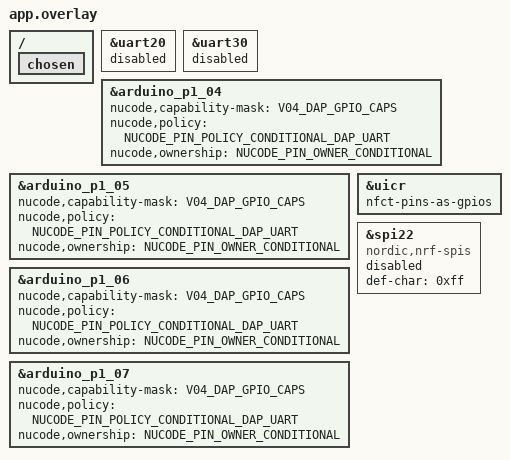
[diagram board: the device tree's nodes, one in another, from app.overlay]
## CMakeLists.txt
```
cmake_minimum_required(VERSION 3.20.0)
find_package(Zephyr REQUIRED HINTS $ENV{ZEPHYR_BASE})
project(v04pair LANGUAGES C CXX)
include(${CMAKE_CURRENT_SOURCE_DIR}/read_revision.cmake)
nucode_hil_revision("${CMAKE_CURRENT_SOURCE_DIR}/../../.." HIL_REVISION)
target_compile_definitions(app PRIVATE NUCODE_HIL_CORE_REVISION="${HIL_REVISION}")
target_sources(app PRIVATE src/main.cpp src/serial_hil.cpp src/fixture_hil.cpp
                           src/signal_hil.cpp)
```

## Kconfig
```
mainmenu "NU54DK v0.4 pair HIL"
source "Kconfig.zephyr"
config NUCODE_V04_HIL_ROLE
    int "Physical role: 1 DUT, 2 peer"
    range 1 2
    default 1
```

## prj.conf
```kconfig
CONFIG_CPP=y
CONFIG_STD_CPP17=y
CONFIG_CPP_EXCEPTIONS=n
CONFIG_CPP_RTTI=n
CONFIG_CONSOLE=n
CONFIG_SERIAL=n
CONFIG_PRINTK=n
CONFIG_LOG=n
CONFIG_ADC=n
CONFIG_PWM=n
CONFIG_I2S=n
CONFIG_SENSOR=n
CONFIG_NUCODE_ARDUINO_CORE=y
CONFIG_NUCODE_ARDUINO_RUNTIME=n
CONFIG_NUCODE_ARDUINO_API=y
CONFIG_NUCODE_ARDUINO_IO_OWNERSHIP=y
CONFIG_NUCODE_ARDUINO_IO_RESOURCE_SLOTS=128
CONFIG_NUCODE_ARDUINO_GPIO=y
CONFIG_NUCODE_ARDUINO_CONNECTOR_GPIO=y
CONFIG_NUCODE_ARDUINO_DAP_UART_GPIO_PINS=y
CONFIG_NUCODE_ARDUINO_INTERRUPTS=n
CONFIG_NUCODE_ARDUINO_TIME=n
CONFIG_NUCODE_ARDUINO_SERIAL=n
CONFIG_NUCODE_ARDUINO_SERIAL_FABRIC=y
CONFIG_NUCODE_ARDUINO_SERIAL_FABRIC_UARTE=y
CONFIG_NUCODE_ARDUINO_SERIAL_FABRIC_SPIM=y
CONFIG_NUCODE_ARDUINO_SERIAL_FABRIC_SPIS=y
CONFIG_NUCODE_ARDUINO_SERIAL_FABRIC_TWIM=y
CONFIG_NUCODE_ARDUINO_SERIAL_FABRIC_TWIS=y
CONFIG_NUCODE_ARDUINO_WIRE=n
CONFIG_NUCODE_ARDUINO_SPI=n
CONFIG_NUCODE_ARDUINO_ADC=n
CONFIG_NUCODE_ARDUINO_PWM=n
CONFIG_NUCODE_ARDUINO_ANALOG_FABRIC=y
CONFIG_NUCODE_ARDUINO_EVENT_FABRIC=y
CONFIG_NUCODE_ARDUINO_STREAM_FABRIC=y
CONFIG_MAIN_STACK_SIZE=8192
```

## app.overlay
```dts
#include <nucode/nu54dk-arduino-pins.dtsi>
/ {
    chosen {
        /delete-property/ zephyr,console;
        /delete-property/ zephyr,shell-uart;
        /delete-property/ zephyr,uart-mcumgr;
        /delete-property/ zephyr,bt-mon-uart;
        /delete-property/ zephyr,bt-c2h-uart;
    };
};
&uart20 { status = "disabled"; };
&uart30 { status = "disabled"; };

/**
 * @brief 이 HIL은 DAP UART 분리 확인 후에만 P1.04~07을 외부 fixture로 사용합니다.
 * @note 일반 board 정책은 유지하며 capability는 DAP UART GPIO Kconfig 조건을 따릅니다.
 */
#define V04_DAP_GPIO_CAPS (NUCODE_PIN_CAP_INPUT | NUCODE_PIN_CAP_OUTPUT | NUCODE_PIN_CAP_ANALOG)
&arduino_p1_04
{
    nucode,capability-mask = <V04_DAP_GPIO_CAPS>;
    nucode,policy = <NUCODE_PIN_POLICY_CONDITIONAL_DAP_UART>;
    nucode,ownership = <NUCODE_PIN_OWNER_CONDITIONAL>;
};
&arduino_p1_05
{
    nucode,capability-mask = <V04_DAP_GPIO_CAPS>;
    nucode,policy = <NUCODE_PIN_POLICY_CONDITIONAL_DAP_UART>;
    nucode,ownership = <NUCODE_PIN_OWNER_CONDITIONAL>;
};
&arduino_p1_06
{
    nucode,capability-mask = <V04_DAP_GPIO_CAPS>;
    nucode,policy = <NUCODE_PIN_POLICY_CONDITIONAL_DAP_UART>;
    nucode,ownership = <NUCODE_PIN_OWNER_CONDITIONAL>;
};
&arduino_p1_07
{
    nucode,capability-mask = <V04_DAP_GPIO_CAPS>;
    nucode,policy = <NUCODE_PIN_POLICY_CONDITIONAL_DAP_UART>;
    nucode,ownership = <NUCODE_PIN_OWNER_CONDITIONAL>;
};
#undef V04_DAP_GPIO_CAPS

/* P1.2/P1.3 are NFC pads unless explicitly released to the PMIC GPIO route. */
&uicr { nfct-pins-as-gpios; };

/* nrfx SPIS needs a compatible node, but no Zephyr driver may claim its IRQ. */
&spi22 {
    compatible = "nordic,nrf-spis";
    /delete-property/ rx-delay-supported;
    /delete-property/ rx-delay;
    def-char = <0xff>;
    status = "disabled";
};
```

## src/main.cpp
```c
// SPDX-License-Identifier: MIT
/** @brief 양쪽 DAP UART level shifter를 분리해도 SWD로 시험을 제어합니다. */
#include "protocol.h"
#include "serial_hil.h"
#include "fixture_hil.h"
#include "signal_hil.h"
#include "pwm_capture_hil.h"
#include "wiring_hil.h"
#include "common_gpio_hil.h"
#include "common_qdec_hil.h"
#include "common_i2s_hil.h"
#include <nucode/AnalogFabric.h>
#include <nucode/EventFabric.h>
#include <nucode/SerialFabric.h>
#include <variant.h>
#include <zephyr/kernel.h>

extern "C"
{
    alignas(4) volatile std::uint32_t v04_request[v04::words]{};
    alignas(4) volatile std::uint32_t v04_response[v04::words]{};
    alignas(4) volatile std::uint32_t v04_identity[16]{};
}

namespace
{
    using namespace nucode::arduino;
    constexpr std::uint32_t role = CONFIG_NUCODE_V04_HIL_ROLE;
    constexpr char revision[] = NUCODE_HIL_CORE_REVISION;
    static_assert(sizeof(revision) == 41);
    alignas(4) std::uint8_t twi_memory[8]{};
    alignas(4) std::int16_t adc_memory[32]{};
    alignas(4) std::uint16_t pwm20_memory[4]{250U, 0U, 0U, 0U};
    alignas(4) std::uint16_t pwm21_memory[4]{0U, 500U, 0U, 0U};

    /** @brief PMIC 시험은 외부 fixture가 해제된 상태에서 읽기 전용으로 실행합니다. */
    std::uint32_t pmic(const std::uint32_t *args, std::uint32_t *out, std::uint32_t &count)
    {
        const auto instance = args[0];
        const auto repeats = args[1];
        if ((instance != 20U && instance != 21U && instance != 22U) || repeats == 0 ||
            repeats > 100 || (args[2] != 100000 && args[2] != 400000))
        {
            return 400;
        }
        auto *handle = serialFabric().twim(instance);
        const SerialSignalPin pins[] = {{SerialSignal::sda, PIN_P1_02},
                                        {SerialSignal::scl, PIN_P1_03}};
        const SerialDmaWorkspace workspace{twi_memory, sizeof(twi_memory)};
        const SerialFabricConfiguration configuration{SerialRouteClass::p1_flexible,
                                                      SerialElectricalProfile::pmic_read_only,
                                                      pins,
                                                      2,
                                                      &workspace,
                                                      1};
        if (handle == nullptr ||
            handle->configure({static_cast<TwiFabricFrequency>(args[2])}) !=
                SerialFabricResult::success ||
            handle->stage(configuration) != SerialFabricResult::success ||
            handle->activate() != SerialFabricResult::success)
        {
            return 501;
        }
        out[0] = 0;
        for (std::uint32_t round = 0; round < repeats; ++round)
        {
            twi_memory[0] = 0x0c;
            twi_memory[1] = 0;
            const auto result = handle->transfer(0x6a, twi_memory, 1, twi_memory + 1, 1, 100000);
            out[3] = static_cast<std::uint32_t>(result);
            if (result != SerialFabricResult::success || twi_memory[1] != 0x41)
            {
                break;
            }
            ++out[0];
            TwiFabricEvent event{};
            while (handle->takeEvent(event))
            {
            }
        }
        out[1] = twi_memory[1];
        out[2] = static_cast<std::uint32_t>(handle->deactivate(100000));
        count = 4;
        return out[0] == repeats && out[2] == 0 ? 0 : 502;
    }

    std::uint32_t timerTest(const std::uint32_t *args, std::uint32_t *out, std::uint32_t &count)
    {
        const auto instance = args[0];
        if (instance != 0 && instance != 10 && (instance < 20 || instance > 24))
        {
            return 400;
        }
        auto *timer = eventFabric().timer(instance);
        if (!timer || args[1] >= timer->channelCount() || args[2] < 1000 || args[2] > 10000)
        {
            return 400;
        }
        if (timer->acquire(1000000) != EventFabricResult::success)
        {
            return 510;
        }
        const bool started = timer->clear() == EventFabricResult::success &&
                             timer->start() == EventFabricResult::success;
        if (started)
        {
            k_busy_wait(args[2]);
        }
        out[0] = timer->capture(args[1]);
        out[1] = static_cast<std::uint32_t>(timer->stop());
        out[2] = static_cast<std::uint32_t>(timer->release());
        count = 3;
        return started && out[1] == 0 && out[2] == 0 ? 0 : 511;
    }

    std::uint32_t adcTest(const std::uint32_t *args, std::uint32_t *out, std::uint32_t &count)
    {
        /** @brief 이 opcode는 외부 패드를 읽거나 구동하지 않는 입력 allowlist만 사용합니다. */
        if ((args[0] != 0x80 && args[0] != 0x82) || args[1] == 0 || args[1] > 32)
        {
            return 400;
        }
        auto &adc = analogFabric().saadc();
        const SaadcChannelConfiguration channel{static_cast<SaadcInput>(args[0]),
                                                SaadcInput::disabled, SaadcGain::one_quarter};
        if (adc.configure({&channel, 1, 12, 1, 0}) != AnalogFabricResult::success ||
            adc.start(adc_memory, args[1], nullptr, 0) != AnalogFabricResult::success)
        {
            return 520;
        }
        bool ready = false, complete = false, failed = false;
        std::uint32_t sampled = 0;
        const auto deadline = k_uptime_get() + 2000;
        while (!complete && !failed && k_uptime_get() < deadline)
        {
            SaadcEvent event{};
            while (adc.takeEvent(event))
            {
                if (event.type == SaadcEventType::ready)
                {
                    ready = true;
                }
                if (event.type == SaadcEventType::error)
                {
                    failed = true;
                }
                if (event.type == SaadcEventType::buffer_complete)
                {
                    complete = event.buffer == adc_memory && event.samples == args[1];
                    failed |= !complete;
                }
            }
            if (ready && sampled < args[1])
            {
                if (adc.sample() != AnalogFabricResult::success)
                {
                    failed = true;
                }
                else
                {
                    ++sampled;
                }
            }
            if (!complete)
            {
                k_sleep(K_MSEC(1));
            }
        }
        out[0] = sampled;
        out[1] = static_cast<std::uint32_t>(adc.stop(100000));
        out[2] = complete ? 1U : 0U;
        if (out[1] != 0)
        {
            count = 3;
            return 522;
        }
        std::int16_t lowest = adc_memory[0], highest = adc_memory[0];
        for (std::size_t index = 0; index < args[1]; ++index)
        {
            if (adc_memory[index] < lowest)
            {
                lowest = adc_memory[index];
            }
            if (adc_memory[index] > highest)
            {
                highest = adc_memory[index];
            }
        }
        out[3] = static_cast<std::uint32_t>(static_cast<std::int32_t>(lowest));
        out[4] = static_cast<std::uint32_t>(static_cast<std::int32_t>(highest));
        count = 5;
        return complete && !failed && out[1] == 0 ? 0 : 521;
    }

    /** @brief 배선 없이 PWM20·PWM21·SAADC EasyDMA가 동시에 활성화되는지 검사합니다. */
    std::uint32_t concurrentAnalogTest(std::uint32_t *out, std::uint32_t &count)
    {
        auto *const pwm20 = analogFabric().pwm(20U);
        auto *const pwm21 = analogFabric().pwm(21U);
        auto &adc = analogFabric().saadc();
        PwmSequenceConfiguration first{};
        PwmSequenceConfiguration second{};
        first.output_pins[0] = PIN_P1_10;
        second.output_pins[1] = PIN_P1_14;
        first.top_value = second.top_value = 1000U;
        first.load = second.load = PwmSequenceLoad::individual;
        const SaadcChannelConfiguration channel{SaadcInput::vdd, SaadcInput::disabled,
                                                SaadcGain::one_quarter};
        if (pwm20 == nullptr || pwm21 == nullptr ||
            pwm20->configure(first) != AnalogFabricResult::success ||
            pwm21->configure(second) != AnalogFabricResult::success)
        {
            return 530U;
        }
        if (pwm20->play({pwm20_memory, 4U, 0U, 0U}, nullptr, 100U, false) !=
            AnalogFabricResult::success)
        {
            return 530U;
        }
        if (pwm21->play({pwm21_memory, 4U, 0U, 0U}, nullptr, 100U, false) !=
            AnalogFabricResult::success)
        {
            (void)pwm20->stop(100000U);
            return 530U;
        }
        if (adc.configure({&channel, 1U, 12U, 1U, 0U}) != AnalogFabricResult::success ||
            adc.start(adc_memory, 32U, nullptr, 0U) != AnalogFabricResult::success)
        {
            (void)pwm21->stop(100000U);
            (void)pwm20->stop(100000U);
            return 530U;
        }
        const bool simultaneous = pwm20->state() == AnalogFabricState::active &&
                                  pwm21->state() == AnalogFabricState::active &&
                                  adc.state() == AnalogFabricState::active;
        bool adc_ready = false;
        bool adc_complete = false;
        bool pwm20_complete = false;
        bool pwm21_complete = false;
        bool failed = false;
        std::uint32_t sampled = 0U;
        const auto deadline = k_uptime_get() + 2000;
        while ((!adc_complete || !pwm20_complete || !pwm21_complete) && !failed &&
               k_uptime_get() < deadline)
        {
            SaadcEvent adc_event{};
            while (adc.takeEvent(adc_event))
            {
                adc_ready |= adc_event.type == SaadcEventType::ready;
                adc_complete |= adc_event.type == SaadcEventType::buffer_complete &&
                                adc_event.buffer == adc_memory && adc_event.samples == 32U;
                failed |= adc_event.type == SaadcEventType::error;
            }
            PwmSequenceEvent pwm_event{};
            while (pwm20->takeEvent(pwm_event))
            {
                pwm20_complete |= pwm_event.type == PwmSequenceEventType::playback_complete;
                failed |= pwm_event.type == PwmSequenceEventType::error;
            }
            while (pwm21->takeEvent(pwm_event))
            {
                pwm21_complete |= pwm_event.type == PwmSequenceEventType::playback_complete;
                failed |= pwm_event.type == PwmSequenceEventType::error;
            }
            if (adc_ready && sampled < 32U)
            {
                if (adc.sample() != AnalogFabricResult::success)
                {
                    failed = true;
                }
                else
                {
                    ++sampled;
                }
            }
            k_sleep(K_MSEC(1));
        }
        const auto adc_stop = adc.stop(100000U);
        const auto pwm21_stop = pwm21->stop(100000U);
        const auto pwm20_stop = pwm20->stop(100000U);
        out[0] = simultaneous;
        out[1] = sampled;
        out[2] = adc_complete;
        out[3] = pwm20_complete;
        out[4] = pwm21_complete;
        out[5] = static_cast<std::uint32_t>(adc_stop);
        out[6] = static_cast<std::uint32_t>(pwm20_stop);
        out[7] = static_cast<std::uint32_t>(pwm21_stop);
        count = 8U;
        return simultaneous && sampled == 32U && adc_complete && pwm20_complete && pwm21_complete &&
                       !failed && adc_stop == AnalogFabricResult::success &&
                       pwm20_stop == AnalogFabricResult::success &&
                       pwm21_stop == AnalogFabricResult::success
                   ? 0U
                   : 531U;
    }

    std::uint32_t dispatch(std::uint32_t opcode, const std::uint32_t *args, std::uint32_t nargs,
                           std::uint32_t *out, std::uint32_t &count)
    {
        if (opcode == 1 && nargs == 4)
        {
            count = 4;
            for (unsigned index = 0; index < count; ++index)
            {
                out[index] = args[index] ^ (0xa5000000U | role);
            }
            return 0;
        }
        if (opcode >= 88U && opcode <= 95U)
        {
            return commonI2sCommand(opcode, args, nargs, out, count);
        }
        if (commonI2sClaimed())
        {
            return 403U;
        }
        if (opcode >= 80U && opcode <= 87U)
        {
            return commonQdecCommand(opcode, args, nargs, out, count);
        }
        if (commonQdecClaimed())
        {
            return 403U;
        }
        if (opcode >= 64U && opcode <= 73U)
        {
            return commonGpioCommand(opcode, args, nargs, out, count);
        }
        if (commonGpioClaimed())
        {
            return 403U;
        }
        if (opcode >= 48U && opcode <= 53U)
        {
            return wiringCommand(opcode, args, nargs, out, count);
        }
        if (wiringClaimed())
        {
            return 403U;
        }
        if ((opcode >= 40U && opcode <= 47U) || (opcode >= 54U && opcode <= 59U))
        {
            return pwmCaptureCommand(opcode, args, nargs, out, count);
        }
        if (pwmCaptureClaimed())
        {
            return 403U;
        }
        if (opcode >= 16 && opcode <= 28)
        {
            return fixtureCommand(opcode, args, nargs, out, count);
        }
        if (opcode >= 32 && opcode <= 39)
        {
            return signalCommand(opcode, args, nargs, out, count);
        }
        if (fixtureClaimed() || signalClaimed())
        {
            return 403;
        }
        if (opcode == 2 && nargs == 3)
        {
            return pmic(args, out, count);
        }
        if (opcode == 3 && nargs == 3)
        {
            return timerTest(args, out, count);
        }
        if (opcode == 4 && nargs == 2)
        {
            return adcTest(args, out, count);
        }
        if (opcode == 5 && nargs == 0)
        {
            return concurrentAnalogTest(out, count);
        }
        if (opcode >= 9 && opcode <= 13)
        {
            return serialOnboard(opcode, args, nargs, out, count);
        }
        return 400;
    }
} // namespace

int main()
{
    initializeWiringIdle();
    initializeOnboardSerialIdle();
    v04_identity[1] = v04::version;
    v04_identity[2] = role;
    for (unsigned index = 0; index < 10; ++index)
    {
        std::uint32_t word = 0;
        for (unsigned byte = 0; byte < 4; ++byte)
        {
            word |= static_cast<std::uint32_t>(revision[index * 4 + byte]) << (byte * 8);
        }
        v04_identity[4 + index] = word;
    }
    __DMB();
    v04_identity[0] = v04::magic;
    std::uint32_t last_sequence = 0;
    std::uint32_t session_nonce[4]{};
    while (true)
    {
        serviceSerial();
        serviceFixture();
        serviceSignal();
        servicePwmCapture();
        serviceWiring();
        serviceCommonGpio();
        serviceCommonQdec();
        serviceCommonI2s();
        if (v04_request[0] != v04::magic)
        {
            if (signalNeedsPolling() || commonGpioNeedsPolling() || commonQdecNeedsPolling() ||
                commonI2sNeedsPolling() || pwmCaptureNeedsPolling())
            {
                k_busy_wait(10U);
            }
            else
            {
                k_sleep(K_MSEC(1));
            }
            continue;
        }
        __DMB();
        std::uint32_t request[v04::words]{}, response[v04::words]{};
        for (unsigned index = 0; index < v04::words; ++index)
        {
            request[index] = v04_request[index];
        }
        v04_request[0] = 0;
        for (unsigned index = 0; index < 9; ++index)
        {
            response[index] = request[index];
        }
        bool same_nonce = true;
        for (unsigned index = 0; index < 4; ++index)
        {
            same_nonce &= request[5 + index] == session_nonce[index];
        }
        if (!v04::valid(request, role) || request[2] != last_sequence + 1 ||
            (last_sequence != 0 && !same_nonce))
        {
            response[9] = 409;
        }
        else
        {
            for (unsigned index = 0; index < 4; ++index)
            {
                session_nonce[index] = request[5 + index];
            }
            last_sequence = request[2];
            response[9] =
                dispatch(request[4], request + 11, request[10], response + 11, response[10]);
        }
        response[31] = v04::checksum(response);
        v04_response[0] = 0;
        for (unsigned index = 1; index < v04::words; ++index)
        {
            v04_response[index] = response[index];
        }
        __DMB();
        v04_response[0] = v04::magic;
    }
}
```

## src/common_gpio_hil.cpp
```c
/**
 * @file common_gpio_hil.cpp
 * @brief 공통 17신호에서 실제 Arduino GPIO와 GPIOTE API를 검사합니다.
 * @note 에지 발생은 CPU가 고정 GPIOTE task를 호출하는 진단 신호원입니다.
 * 정밀 주기나 IRQ latency를 보증하지 않으며 실제 count와 최대 poll 간격을 보고합니다.
 * SPDX-License-Identifier: MIT
 */
#include "common_gpio_hil.h"
#include "common_wiring.h"
#include "fixture_gate.h"
#include "fixture_hil.h"
#include "pwm_capture_hil.h"
#include "signal_hil.h"
#include "wiring_hil.h"
#include "serial_hil.h"
#include <Arduino.h>
#include <variant.h>
#include <internal/PinHandover.h>
#include <internal/pin_description.h>
#include <nucode/EventFabric.h>
#include <hal/nrf_gpio.h>
#include <hal/nrf_gpiote.h>
#include <zephyr/kernel.h>

namespace
{
    using namespace nucode::arduino;
    using namespace nucode::arduino::internal;
    constexpr std::uint32_t role = CONFIG_NUCODE_V04_HIL_ROLE;
    v04::FixtureGate gate;
    std::uint32_t net = v04::wiring_none;
    bool gpio_owned = false, gpiote_owned = false;
    bool output = false, generating = false;
    GpioteFabric *gpiote = nullptr;
    std::uint32_t channel = 0U, edge_count = 0U, emitted = 0U, error = 0U;
    std::uint32_t limit = 0U, interval_cycles = 0U, last_edge = 0U, last_poll = 0U;
    std::uint32_t max_poll_cycles = 0U, leakage = 0U, lease_expirations = 0U;

    /** @brief Arduino ID와 물리 net을 분리하고 I2S의 두 교차 선을 반영합니다. */
    pin_size_t logical(std::uint32_t selected)
    {
        constexpr pin_size_t pins[]{PIN_P1_14, PIN_P1_10, PIN_P1_04, PIN_P1_05, PIN_P1_06,
                                    PIN_P1_07, PIN_P0_00, PIN_P0_01, PIN_P0_02, PIN_P0_03,
                                    PIN_P2_00, PIN_P2_01, PIN_P2_02, PIN_P2_03, PIN_P2_04,
                                    PIN_P2_05, PIN_P2_06};
        if (selected >= v04::wiring_count)
        {
            return static_cast<pin_size_t>(UINT16_MAX);
        }
        return pins[role == 2U && (selected == 4U || selected == 5U) ? 9U - selected : selected];
    }

    /** @brief 현재 소유한 GPIOTE 레지스터만 진단 대상으로 선택합니다. */
    NRF_GPIOTE_Type *reg()
    {
        return gpiote != nullptr && gpiote->instance() == 30U ? NRF_GPIOTE30 : NRF_GPIOTE20;
    }

    /** @brief GPIO 입력 전환 뒤 내부 handover로 GPIO lease도 반환합니다. */
    bool releaseGpio()
    {
        if (!gpio_owned)
        {
            return true;
        }
        pinMode(logical(net), INPUT);
        if (lastGpioError() != GpioError::none)
        {
            return false;
        }
        GpioPinHandover handover{};
        if (beginGpioPinHandover(logical(net), {IoOwnerKind::application, 242U}, handover) !=
            PinHandoverResult::success)
        {
            return false;
        }
        if (commitGpioPinHandover(handover) != PinHandoverResult::success)
        {
            return false;
        }
        nrf_gpio_cfg_input(v04::wiringPin(role, net), NRF_GPIO_PIN_NOPULL);
        if (releasePeripheralPinHandover(handover) != PinHandoverResult::success)
        {
            return false;
        }
        gpio_owned = false;
        return true;
    }

    /** @brief 생성기를 먼저 중지한 뒤 검증 가능한 입력·free 상태로 돌립니다. */
    bool stop()
    {
        generating = false;
        if (gpiote_owned)
        {
            if (gpiote->release(static_cast<std::uint8_t>(channel)) != EventFabricResult::success)
            {
                return false;
            }
            gpiote_owned = false;
        }
        if (!releaseGpio())
        {
            return false;
        }
        if (net != v04::wiring_none &&
            nrf_gpio_pin_dir_get(v04::wiringPin(role, net)) != NRF_GPIO_PIN_DIR_INPUT)
        {
            return false;
        }
        net = v04::wiring_none;
        output = false;
        gpiote = nullptr;
        return true;
    }

    /** @brief 다른 신호를 구동하지 않았는지 전체 net의 방향을 원본으로 반환합니다. */
    std::uint32_t directionMask()
    {
        std::uint32_t mask = 0U;
        for (unsigned index = 0U; index < v04::wiring_count; ++index)
        {
            mask |=
                (nrf_gpio_pin_dir_get(v04::wiringPin(role, index)) == NRF_GPIO_PIN_DIR_OUTPUT ? 1U
                                                                                              : 0U)
                << index;
        }
        return mask;
    }

    /** @brief API 판정 전에 물리 level·설정·상태·누출을 그대로 제공합니다. */
    void snapshot(std::uint32_t *out, std::uint32_t &count)
    {
        out[0] = net;
        out[1] = net == v04::wiring_none ? 0U : nrf_gpio_pin_read(v04::wiringPin(role, net));
        out[2] = gpio_owned ? static_cast<std::uint32_t>(digitalRead(logical(net))) : UINT32_MAX;
        out[3] = directionMask();
        out[4] = 0U;
        if (net != v04::wiring_none)
        {
            auto physical = v04::wiringPin(role, net);
            auto *const port = nrf_gpio_pin_port_decode(&physical);
            out[4] = port->PIN_CNF[physical];
        }
        out[5] = edge_count;
        out[6] = emitted;
        out[7] = generating;
        out[8] = error;
        out[9] = leakage;
        out[10] = k_cyc_to_us_floor32(max_poll_cycles);
        out[11] = lease_expirations;
        out[12] = gpiote == nullptr ? 0U : gpiote->channelCount();
        out[13] = gpio_owned;
        out[14] = gpiote_owned;
        out[15] = gate.live(k_uptime_get());
        count = 16U;
    }
} // namespace

bool commonGpioClaimed()
{
    return gate.claimed();
}

bool commonGpioNeedsPolling()
{
    return gpiote_owned;
}

void serviceCommonGpio()
{
    if (gate.fixture() && !gate.live(k_uptime_get()))
    {
        ++lease_expirations;
        error = 1U;
        gate.close(stop());
    }
    if (!gpiote_owned)
    {
        return;
    }
    const auto now = k_cycle_get_32();
    const auto gap = now - last_poll;
    if (last_poll != 0U && gap > max_poll_cycles)
    {
        max_poll_cycles = gap;
    }
    last_poll = now;
    if (generating && now - last_edge >= interval_cycles)
    {
        last_edge = now;
        *reinterpret_cast<volatile std::uint32_t *>(gpiote->outTask(channel).address) = 1U;
        ++emitted;
        if (emitted == limit)
        {
            generating = false;
        }
    }
    for (unsigned index = 0U; index < gpiote->channelCount(); ++index)
    {
        const auto event = nrf_gpiote_in_event_get(index);
        if (nrf_gpiote_event_check(reg(), event))
        {
            nrf_gpiote_event_clear(reg(), event);
            if (index == channel && !output)
            {
                ++edge_count;
            }
            else
            {
                leakage |= 1U << index;
            }
        }
    }
}

std::uint32_t commonGpioCommand(std::uint32_t opcode, const std::uint32_t *args,
                                std::uint32_t nargs, std::uint32_t *out, std::uint32_t &count)
{
    serviceCommonGpio();
    if (opcode == 64U && nargs == 4U)
    {
        if (fixtureClaimed() || signalClaimed() || pwmCaptureClaimed() || wiringClaimed() ||
            onboardSerialActive() || args[0] != 502U ||
            !gate.arm(args[0], args[1], args[2], args[3], role, k_uptime_get()))
        {
            return 403U;
        }
        error = edge_count = emitted = leakage = max_poll_cycles = last_poll = 0U;
        out[0] = 502U;
        out[1] = 10000U;
        count = 2U;
        return 0U;
    }
    if (opcode == 65U && nargs == 0U)
    {
        const bool result = stop();
        gate.close(result);
        snapshot(out, count);
        return result ? 0U : 760U;
    }
    if (opcode == 68U && nargs == 0U)
    {
        snapshot(out, count);
        return 0U;
    }
    if (!gate.live(k_uptime_get()))
    {
        return 403U;
    }
    if (opcode == 69U && nargs == 0U)
    {
        out[0] = gate.renew(k_uptime_get()) ? 0U : 1U;
        count = 1U;
        return 0U;
    }
    if (opcode == 66U && nargs == 2U && args[0] < v04::wiring_count && args[1] < 5U &&
        !gpiote_owned && (net == v04::wiring_none || net == args[0]) &&
        (args[1] < 3U || gate.controller() == role))
    {
        constexpr PinMode modes[]{INPUT, INPUT_PULLUP, INPUT_PULLDOWN, OUTPUT, OUTPUT_OPENDRAIN};
        net = args[0];
        pinMode(logical(net), modes[args[1]]);
        out[0] = static_cast<std::uint32_t>(lastGpioError());
        gpio_owned |= out[0] == 0U;
        output = args[1] >= 3U && out[0] == 0U;
        count = 1U;
        return 0U;
    }
    if (opcode == 67U && nargs == 1U && args[0] <= 1U && gpio_owned && output &&
        gate.controller() == role)
    {
        digitalWrite(logical(net), args[0] ? HIGH : LOW);
        out[0] = static_cast<std::uint32_t>(lastGpioError());
        count = 1U;
        return 0U;
    }
    if (opcode == 70U && nargs == 4U && args[0] < 10U && args[1] < 8U && args[2] < 3U &&
        args[3] <= 1U && !gpio_owned && !gpiote_owned && net == v04::wiring_none &&
        (args[3] == 0U || gate.controller() == role))
    {
        net = args[0];
        channel = args[1];
        output = args[3] != 0U;
        gpiote = eventFabric().gpiote(net < 6U ? 20U : 30U);
        const auto polarity = static_cast<GpiotePolarity>(args[2]);
        const auto result = output ? gpiote->acquireOutput(channel, logical(net), polarity, false)
                                   : gpiote->acquireInput(channel, logical(net), polarity);
        gpiote_owned = result == EventFabricResult::success;
        out[0] = static_cast<std::uint32_t>(result);
        out[1] = gpiote->channelCount();
        count = 2U;
        if (gpiote_owned)
        {
            for (unsigned index = 0U; index < gpiote->channelCount(); ++index)
            {
                nrf_gpiote_event_clear(reg(), nrf_gpiote_in_event_get(index));
            }
        }
        return 0U;
    }
    if (opcode == 71U && nargs == 1U && args[0] < 3U && gpiote_owned && output && !generating)
    {
        const auto endpoint = args[0] == 0U   ? gpiote->outTask(channel)
                              : args[0] == 1U ? gpiote->setTask(channel)
                                              : gpiote->clearTask(channel);
        *reinterpret_cast<volatile std::uint32_t *>(endpoint.address) = 1U;
        out[0] = 0U;
        count = 1U;
        return 0U;
    }
    if (opcode == 72U && nargs == 2U && (args[0] == 100U || args[0] == 1000U) && args[1] == 1000U &&
        gpiote_owned && output && !generating && emitted == 0U)
    {
        interval_cycles = k_us_to_cyc_ceil32(1000000U / args[0]);
        limit = args[1];
        last_edge = k_cycle_get_32();
        generating = true;
        out[0] = 0U;
        count = 1U;
        return 0U;
    }
    if (opcode == 73U && nargs == 1U && args[0] < 3U && !gpio_owned && !gpiote_owned)
    {
        out[1] = directionMask();
        if (args[0] == 0U)
        {
            pinMode(static_cast<pin_size_t>(UINT16_MAX), OUTPUT);
            out[0] = static_cast<std::uint32_t>(lastGpioError());
        }
        else
        {
            auto *const handle = eventFabric().gpiote(args[0] == 1U ? 20U : 30U);
            const auto selected = args[0] == 1U ? handle->channelCount() : 0U;
            const auto result = handle->acquireInput(selected, PIN_P1_14, GpiotePolarity::toggle);
            out[0] = static_cast<std::uint32_t>(result);
            if (result == EventFabricResult::success)
            {
                /** @brief 예상 밖 성공도 입력만 획득했으며 즉시 반환하고 실패로 보고합니다. */
                (void)handle->release(selected);
            }
        }
        out[2] = directionMask();
        count = 3U;
        return 0U;
    }
    return 400U;
}
```

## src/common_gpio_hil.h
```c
/**
 * @file common_gpio_hil.h
 * @brief 공통 결선의 Arduino GPIO와 GPIOTE 기능 명령을 선언합니다.
 * SPDX-License-Identifier: MIT
 */
#pragma once
#include <cstdint>

/** @brief 다른 fixture와 배타적으로 사용하는 실행 상태입니다. */
bool commonGpioClaimed();
/** @brief 유한 에지 생성·관측과 10초 lease 만료를 처리합니다. */
void serviceCommonGpio();
/** @brief 에지를 놓치지 않도록 짧은 main poll이 필요한지 반환합니다. */
bool commonGpioNeedsPolling();
/** @brief 고정 net만 허용하는 GPIO/GPIOTE 명령입니다. */
std::uint32_t commonGpioCommand(std::uint32_t opcode, const std::uint32_t *args,
                                std::uint32_t nargs, std::uint32_t *out, std::uint32_t &count);
```

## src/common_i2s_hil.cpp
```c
/**
 * @file common_i2s_hil.cpp
 * @brief 3개 DMA slot을 순환하며 초기 4개와 측정 100개 buffer를 보존합니다.
 * @note 이후 Host STOP까지 공급한 tail은 측정 100개에 더하지 않습니다.
 * SPDX-License-Identifier: MIT
 */
#include "common_i2s_hil.h"
#include "common_qdec_hil.h"
#include "common_gpio_hil.h"
#include "common_wiring.h"
#include "fixture_gate.h"
#include "fixture_hil.h"
#include "pwm_capture_hil.h"
#include "signal_hil.h"
#include "wiring_hil.h"
#include "serial_hil.h"
#include "i2s_stream_oracle.h"
#include <nucode/StreamFabric.h>
#include <variant.h>
#include <hal/nrf_gpio.h>
#include <zephyr/kernel.h>

namespace
{
    using namespace nucode::arduino;
    constexpr std::uint32_t role = CONFIG_NUCODE_V04_HIL_ROLE;
    constexpr std::uint32_t slots = 3U, measured_end = 104U, guard = 0xA55A9669U;
    struct alignas(4) Buffer
    {
        std::uint32_t memory[1032];
        /** @brief 요청 길이 직후에 16-byte guard를 두며 capacity 끝으로 미루지 않습니다. */
        std::uint32_t *data()
        {
            return memory + 4U;
        }
    } rx[slots]{}, tx[slots]{};
    v04::FixtureGate gate;
    I2sFabric *i2s = nullptr;
    v04::I2sStreamOracle oracle;
    bool prepared = false, started = false, receive = false, transmit = false;
    bool active_slots[slots]{};
    std::uint32_t completed = 0U, queued = 0U, error = 0U, rate = 0U, width = 0U;
    std::uint32_t channels = 0U, words = 0U, seed = 0U, origin = 0U, max_queue_us = 0U;
    std::uint32_t lease_expirations = 0U;
    std::uint32_t statistics[measured_end][5]{};

    /** @brief slot의 앞뒤 guard를 요청 길이에 맞추어 설정합니다. */
    void initialize(Buffer &buffer)
    {
        for (unsigned index = 0U; index < 4U; ++index)
        {
            buffer.memory[index] = buffer.memory[words + 4U + index] = guard;
        }
    }

    /** @brief 측정/대기/활성 slot 모두의 앞뒤 guard를 읽습니다. */
    bool guards()
    {
        for (unsigned slot = 0U; slot < slots; ++slot)
        {
            for (unsigned index = 0U; index < 4U; ++index)
            {
                if (rx[slot].memory[index] != guard ||
                    rx[slot].memory[words + 4U + index] != guard ||
                    tx[slot].memory[index] != guard || tx[slot].memory[words + 4U + index] != guard)
                {
                    return false;
                }
            }
        }
        return true;
    }

    /** @brief 순환 slot에 다음 고유 전역 word 위치를 채웁니다. */
    void fill(std::uint32_t slot, std::uint32_t index)
    {
        for (unsigned word = 0U; word < words; ++word)
        {
            tx[slot].data()[word] = v04::i2sStreamPattern(seed, index * words + word);
            rx[slot].data()[word] = 0xCCCCCCCCU;
        }
    }

    /** @brief 한쪽 DMA를 비활성화할 때는 실제 nullptr로 전달합니다. */
    I2sBuffers buffers(std::uint32_t slot)
    {
        return {receive ? rx[slot].data() : nullptr, transmit ? tx[slot].data() : nullptr, words};
    }

    /** @brief STOP이 증명된 뒤에만 stream과 pin을 반환합니다. */
    bool stop()
    {
        if (i2s != nullptr && i2s->state() == StreamFabricState::faulted)
        {
            return false;
        }
        if (i2s != nullptr && (i2s->state() == StreamFabricState::active ||
                               i2s->state() == StreamFabricState::stopping))
        {
            if (i2s->stop(100000U) != StreamFabricResult::success)
            {
                return false;
            }
            for (unsigned pin = 4U; pin <= 7U; ++pin)
            {
                nrf_gpio_cfg_input(NRF_GPIO_PIN_MAP(1, pin), NRF_GPIO_PIN_NOPULL);
            }
        }
        started = prepared = false;
        i2s = nullptr;
        return true;
    }

    /** @brief 완료와 재사용 전에 반환 pointer·크기·guard를 검증합니다. */
    void released(const I2sBuffers &result)
    {
        const auto slot = completed % slots;
        const auto expected = buffers(slot);
        if (!active_slots[slot] || result.receive != expected.receive ||
            result.transmit != expected.transmit || result.words != words || !guards())
        {
            error = 2U;
            return;
        }
        active_slots[slot] = false;
        if (completed < measured_end)
        {
            const auto mask = width == 24U ? 0xFFFFFFU : UINT32_MAX;
            auto crc = UINT32_MAX;
            for (unsigned index = 0U; index < words; ++index)
            {
                if (receive)
                {
                    const auto raw = result.receive[index];
                    oracle.consume(raw);
                    crc = v04::i2sCrcWord(crc, raw & mask);
                }
            }
            statistics[completed][0] = completed;
            statistics[completed][1] = k_cyc_to_us_floor32(k_cycle_get_32() - origin);
            statistics[completed][2] = receive ? crc ^ UINT32_MAX : 0U;
            statistics[completed][3] = receive ? result.receive[0] & mask : 0U;
            statistics[completed][4] = receive ? result.receive[words - 1U] & mask : 0U;
            if (oracle.mismatches != 0U)
            {
                error = 3U;
            }
        }
        ++completed;
    }

    /** @brief 측정과 tail, 실제 단방향 설정 및 출력 방향을 구분하여 반환합니다. */
    void snapshot(std::uint32_t *out, std::uint32_t &count)
    {
        std::uint32_t direction = 0U;
        for (unsigned net = 0U; net < v04::wiring_count; ++net)
        {
            direction |=
                (nrf_gpio_pin_dir_get(v04::wiringPin(role, net)) == NRF_GPIO_PIN_DIR_OUTPUT ? 1U
                                                                                            : 0U)
                << net;
        }
        const std::uint32_t values[]{prepared,
                                     started,
                                     completed,
                                     queued,
                                     completed < measured_end ? completed : measured_end,
                                     error,
                                     guards(),
                                     oracle.padding,
                                     receive,
                                     transmit,
                                     oracle.samples,
                                     oracle.mismatches,
                                     max_queue_us,
                                     rate,
                                     width,
                                     channels,
                                     words,
                                     direction,
                                     lease_expirations,
                                     gate.live(k_uptime_get())};
        for (unsigned index = 0U; index < 20U; ++index)
        {
            out[index] = values[index];
        }
        count = 20U;
    }
} // namespace

bool commonI2sClaimed()
{
    return gate.claimed();
}

bool commonI2sNeedsPolling()
{
    return started;
}

void serviceCommonI2s()
{
    if (gate.fixture() && !gate.live(k_uptime_get()))
    {
        ++lease_expirations;
        error = 1U;
        gate.close(stop());
    }
    if (!started || i2s == nullptr)
    {
        return;
    }
    I2sEvent event{};
    while (i2s->takeEvent(event))
    {
        if (event.type == I2sEventType::buffers_complete)
        {
            released(event.released);
        }
        else if (event.type == I2sEventType::buffers_needed && error == 0U)
        {
            const auto slot = queued % slots;
            if (active_slots[slot])
            {
                error = 4U;
                break;
            }
            const auto before = k_cycle_get_32();
            fill(slot, queued);
            const auto result = i2s->queueBuffers(buffers(slot));
            const auto elapsed = k_cyc_to_us_floor32(k_cycle_get_32() - before);
            if (elapsed > max_queue_us)
            {
                max_queue_us = elapsed;
            }
            if (result != StreamFabricResult::success)
            {
                error = 5U;
                break;
            }
            active_slots[slot] = true;
            ++queued;
        }
        else if (event.type == I2sEventType::underrun || event.type == I2sEventType::error ||
                 event.type == I2sEventType::stopped)
        {
            error = 6U;
        }
        if (error != 0U)
        {
            break;
        }
    }
    if (error != 0U)
    {
        gate.close(stop());
    }
}

std::uint32_t commonI2sCommand(std::uint32_t opcode, const std::uint32_t *args, std::uint32_t nargs,
                               std::uint32_t *out, std::uint32_t &count)
{
    serviceCommonI2s();
    if (opcode == 88U && nargs == 4U)
    {
        if (fixtureClaimed() || signalClaimed() || pwmCaptureClaimed() || wiringClaimed() ||
            commonGpioClaimed() || commonQdecClaimed() || onboardSerialActive() ||
            args[0] != 530U || !gate.arm(args[0], args[1], args[2], args[3], role, k_uptime_get()))
        {
            return 403U;
        }
        error = completed = queued = max_queue_us = 0U;
        out[0] = 530U;
        out[1] = 10000U;
        count = 2U;
        return 0U;
    }
    if (opcode == 89U && nargs == 0U)
    {
        const bool result = stop();
        gate.close(result);
        snapshot(out, count);
        return result ? 0U : 780U;
    }
    if (opcode == 92U && nargs == 0U)
    {
        snapshot(out, count);
        return 0U;
    }
    if (opcode == 93U && nargs == 2U && args[1] > 0U && args[1] <= 4U && args[0] < measured_end &&
        args[1] <= measured_end - args[0] && args[0] + args[1] <= completed)
    {
        for (unsigned index = 0U; index < args[1]; ++index)
        {
            for (unsigned field = 0U; field < 5U; ++field)
            {
                out[index * 5U + field] = statistics[args[0] + index][field];
            }
        }
        count = args[1] * 5U;
        return 0U;
    }
    if (opcode == 95U && nargs == 0U)
    {
        out[0] = oracle.first_index;
        out[1] = oracle.first_expected;
        out[2] = oracle.first_actual;
        out[3] = error;
        count = 4U;
        return 0U;
    }
    if (!gate.live(k_uptime_get()))
    {
        return 403U;
    }
    if (opcode == 94U && nargs == 0U)
    {
        out[0] = gate.renew(k_uptime_get()) ? 0U : 1U;
        count = 1U;
        return 0U;
    }
    if (opcode == 90U && nargs == 6U && !prepared && !started &&
        (args[0] == 16000U || args[0] == 48000U) &&
        (args[1] == 8U || args[1] == 16U || args[1] == 24U || args[1] == 32U) && args[2] <= 2U &&
        (args[3] == 32U || args[3] == 256U || args[3] == 1024U) && args[4] >= 1U && args[4] <= 3U)
    {
        rate = args[0];
        width = args[1];
        channels = args[2];
        words = args[3];
        transmit = (args[4] & (role == 1U ? 1U : 2U)) != 0U;
        receive = (args[4] & (role == 1U ? 2U : 1U)) != 0U;
        seed = args[5] ^ (role == 1U ? 0U : 0x5A5A5A5AU);
        oracle.reset(args[5] ^ (role == 1U ? 0x5A5A5A5AU : 0U), width, channels);
        for (unsigned slot = 0U; slot < slots; ++slot)
        {
            initialize(rx[slot]);
            initialize(tx[slot]);
            active_slots[slot] = false;
        }
        i2s = streamFabric().i2s(20U);
        const I2sConfiguration configuration{PIN_P1_04,
                                             PIN_P1_05,
                                             0xFFU,
                                             static_cast<pin_size_t>(transmit ? PIN_P1_06 : 0xFFU),
                                             static_cast<pin_size_t>(receive ? PIN_P1_07 : 0xFFU),
                                             rate,
                                             static_cast<I2sSampleWidth>(width),
                                             static_cast<I2sChannels>(channels),
                                             gate.controller() == role,
                                             StreamElectricalProfile::dap_uart_disabled};
        prepared = i2s != nullptr && i2s->configure(configuration) == StreamFabricResult::success;
        out[0] = prepared ? 0U : 1U;
        count = 1U;
        return 0U;
    }
    if (opcode == 91U && nargs == 0U && prepared && !started)
    {
        fill(0U, 0U);
        origin = k_cycle_get_32();
        started = i2s->start(buffers(0U)) == StreamFabricResult::success;
        active_slots[0] = started;
        queued = started ? 1U : 0U;
        out[0] = started ? 0U : 1U;
        count = 1U;
        return 0U;
    }
    return 400U;
}
```

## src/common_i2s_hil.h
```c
/**
 * @file common_i2s_hil.h
 * @brief 공통 4선의 연속·단방향 I2S 시험입니다.
 * SPDX-License-Identifier: MIT
 */
#pragma once
#include <cstdint>
/** @brief 다른 외부 시험과의 배타 상태입니다. */
bool commonI2sClaimed();
/** @brief DMA 반환·공급·검증·lease 만료를 처리합니다. */
void serviceCommonI2s();
/** @brief 짧은 poll이 필요한지 반환합니다. */
bool commonI2sNeedsPolling();
/** @brief 고정 530 결선 명령만 허용합니다. */
std::uint32_t commonI2sCommand(std::uint32_t opcode, const std::uint32_t *args, std::uint32_t nargs,
                               std::uint32_t *out, std::uint32_t &count);
```

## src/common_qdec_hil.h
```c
/**
 * @file common_qdec_hil.h
 * @brief 공통 P1.14/P1.10 QDEC 추가 기능 시험입니다.
 * SPDX-License-Identifier: MIT
 */
#pragma once
#include <cstdint>
/** @brief 다른 외부 시험과 배타적인 소유 상태입니다. */
bool commonQdecClaimed();
/** @brief 유한 quadrature 생성·누산기 배출·lease 만료를 처리합니다. */
void serviceCommonQdec();
/** @brief 짧은 poll이 필요한 상태인지 반환합니다. */
bool commonQdecNeedsPolling();
/** @brief 임의 pin 없이 520 명령만 처리합니다. */
std::uint32_t commonQdecCommand(std::uint32_t opcode, const std::uint32_t *args,
                                std::uint32_t nargs, std::uint32_t *out, std::uint32_t &count);
```

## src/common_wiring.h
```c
/**
 * @file common_wiring.h
 * @brief 공통 17신호의 고정 대응과 단일 LOW의 제한 시간을 정의합니다.
 * SPDX-License-Identifier: MIT
 */
#pragma once
#include <cstdint>

namespace v04
{
    inline constexpr std::uint32_t wiring_count = 17U;
    inline constexpr std::uint32_t wiring_mask = (1U << wiring_count) - 1U;
    inline constexpr std::uint32_t wiring_none = UINT32_MAX;

    /** @brief GPIO의 port*32+pin 번호이며 Arduino 별칭과 connector 번호가 아닙니다. */
    constexpr std::uint32_t wiringPin(std::uint32_t role, std::uint32_t net)
    {
        constexpr std::uint32_t pins[]{46U, 42U, 36U, 37U, 38U, 39U, 0U,  1U, 2U,
                                       3U,  64U, 65U, 66U, 67U, 68U, 69U, 70U};
        if ((role != 1U && role != 2U) || net >= wiring_count)
        {
            return wiring_none;
        }
        if (role == 2U && (net == 4U || net == 5U))
        {
            return pins[9U - net];
        }
        return pins[net];
    }

    /** @brief Host가 응답하지 않아도 한 LOW를 500ms 안에 해제할 상태입니다. */
    class WiringPulse
    {
      public:
        static constexpr std::uint64_t limit_ms = 500U;

        constexpr bool start(std::uint32_t net, std::uint64_t now)
        {
            if (net >= wiring_count || net_ != wiring_none || now > UINT64_MAX - limit_ms)
            {
                return false;
            }
            net_ = net;
            deadline_ = now + limit_ms;
            return true;
        }

        constexpr bool expired(std::uint64_t now) const
        {
            return net_ != wiring_none && now >= deadline_;
        }

        constexpr void clear()
        {
            net_ = wiring_none;
            deadline_ = 0U;
        }

        constexpr std::uint32_t net() const
        {
            return net_;
        }

      private:
        std::uint32_t net_ = wiring_none;
        std::uint64_t deadline_ = 0U;
    };
} // namespace v04
```

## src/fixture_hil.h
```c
/**
 * @file fixture_hil.h
 * @brief 결선 확인 뒤에만 실행하는 외부 통신 시험 명령입니다.
 * SPDX-License-Identifier: MIT
 */
#pragma once
#include <cstdint>

/** @brief 외부 시험의 이벤트와 실행 허가 만료를 처리합니다. */
void serviceFixture();
/** @brief 외부 시험이 온보드 핀 사용을 막고 있는지 반환합니다. */
bool fixtureClaimed();
/** @brief 고정 결선 명령을 처리하며 임의 핀 주소를 받지 않습니다. */
std::uint32_t fixtureCommand(std::uint32_t opcode, const std::uint32_t *args, std::uint32_t nargs,
                             std::uint32_t *out, std::uint32_t &count);
```

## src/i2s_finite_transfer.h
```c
/**
 * @file i2s_finite_transfer.h
 * @brief 연속 I2S에서 유한 payload와 마지막 반환용 tail buffer의 순서를 관리합니다.
 * SPDX-License-Identifier: MIT
 */
#pragma once
#include <cstdint>

namespace v04
{
    class I2sFiniteTransfer
    {
      public:
        /** @brief slot 0으로 시작한 단일/이중 payload의 다음 요청을 준비합니다. */
        void reset(std::uint32_t buffers)
        {
            buffers_ = buffers;
            next_ = 1U;
            completed_ = 0U;
        }

        /** @brief 다음 payload, tail slot 2, 정지 보호용 slot 3 순서로 반환합니다. */
        std::uint32_t nextSlot() const
        {
            return next_ < buffers_ ? next_ : 2U + next_ - buffers_;
        }

        /** @brief driver가 다음 buffer를 실제로 수락한 뒤에만 진행합니다. */
        void queued()
        {
            ++next_;
        }

        /** @brief 제출되지 않은 slot·tail·중복 반환을 payload 완료로 인정하지 않습니다. */
        bool released(std::uint32_t slot)
        {
            if (slot >= buffers_ || slot >= next_ || (completed_ & (1U << slot)) != 0U)
            {
                return false;
            }
            completed_ |= 1U << slot;
            return true;
        }

        /** @brief 모든 요청 payload가 각각 반환되었는지 확인합니다. */
        bool complete() const
        {
            return completed_ == ((1U << buffers_) - 1U);
        }

      private:
        std::uint32_t buffers_ = 1U;
        std::uint32_t next_ = 1U;
        std::uint32_t completed_ = 0U;
    };
} // namespace v04
```
